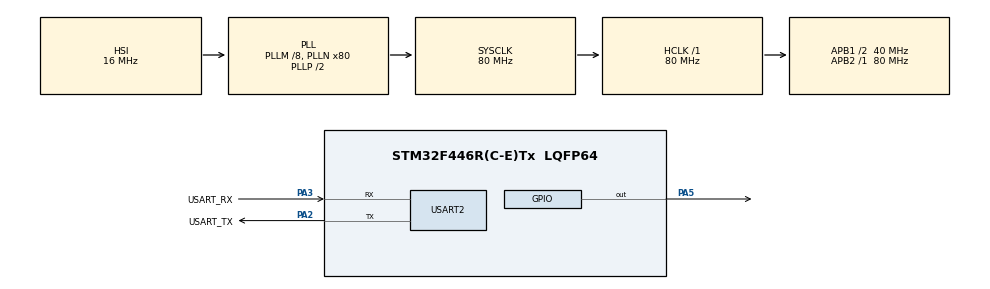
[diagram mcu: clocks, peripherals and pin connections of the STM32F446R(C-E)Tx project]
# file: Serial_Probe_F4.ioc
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Dma.Request0=USART2_RX
Dma.Request1=USART2_TX
Dma.USART2_RX.0.Direction=DMA_PERIPH_TO_MEMORY
Dma.USART2_RX.0.FIFOMode=DMA_FIFOMODE_DISABLE
Dma.USART2_RX.0.Instance=DMA1_Stream5
Dma.USART2_RX.0.MemDataAlignment=DMA_MDATAALIGN_BYTE
Dma.USART2_RX.0.MemInc=DMA_MINC_ENABLE
Dma.USART2_RX.0.Mode=DMA_CIRCULAR
Dma.USART2_RX.0.PeriphDataAlignment=DMA_PDATAALIGN_BYTE
Dma.USART2_RX.0.PeriphInc=DMA_PINC_DISABLE
Dma.USART2_RX.0.Priority=DMA_PRIORITY_LOW
Dma.USART2_TX.1.Direction=DMA_MEMORY_TO_PERIPH
Dma.USART2_TX.1.FIFOMode=DMA_FIFOMODE_DISABLE
Dma.USART2_TX.1.Instance=DMA1_Stream6
Dma.USART2_TX.1.MemDataAlignment=DMA_MDATAALIGN_BYTE
Dma.USART2_TX.1.MemInc=DMA_MINC_ENABLE
Dma.USART2_TX.1.Mode=DMA_NORMAL
Dma.USART2_TX.1.PeriphDataAlignment=DMA_PDATAALIGN_BYTE
Dma.USART2_TX.1.PeriphInc=DMA_PINC_DISABLE
Dma.USART2_TX.1.Priority=DMA_PRIORITY_LOW
Mcu.Family=STM32F4
Mcu.Name=STM32F446R(C-E)Tx
Mcu.Package=LQFP64
NVIC.DMA1_Stream5_IRQn=true\:1\:0\:true\:true\:true\:3\:false\:true\:true
NVIC.DMA1_Stream6_IRQn=true\:1\:0\:true\:true\:true\:2\:false\:true\:true
NVIC.PriorityGroup=NVIC_PRIORITYGROUP_4
NVIC.TIM6_DAC_IRQn=true\:1\:0\:true\:true\:true\:4\:true\:true\:true
NVIC.USART2_IRQn=true\:1\:0\:true\:true\:true\:1\:true\:true\:true
PA2.GPIO_Label=USART_TX
PA2.Mode=Asynchronous
PA2.Signal=USART2_TX
PA3.GPIO_Label=USART_RX
PA3.Mode=Asynchronous
PA3.Signal=USART2_RX
PA5.Signal=GPIO_Output
ProjectManager.HeapSize=0x200
ProjectManager.StackSize=0x400
ProjectManager.TargetToolchain=STM32CubeIDE
RCC.48MHZClocksFreq_Value=84000000
RCC.AHBFreq_Value=80000000
RCC.APB1CLKDivider=RCC_HCLK_DIV2
RCC.APB1Freq_Value=40000000
RCC.APB1TimFreq_Value=80000000
RCC.APB2Freq_Value=80000000
RCC.APB2TimFreq_Value=80000000
RCC.CortexFreq_Value=80000000
RCC.FLatency-AdvancedSettings=FLASH_LATENCY_2
RCC.HCLKFreq_Value=80000000
RCC.HSE_VALUE=8000000
RCC.HSI_VALUE=16000000
RCC.PLLM=8
RCC.PLLN=80
RCC.SYSCLKFreq_VALUE=80000000
RCC.SYSCLKSource=RCC_SYSCLKSOURCE_PLLCLK
RCC.USBFreq_Value=80000000
RCC.VCOOutputFreq_Value=160000000
TIM6.Period=99
TIM6.Prescaler=7999
USART2.VirtualMode=VM_ASYNC
VP_TIM6_VS_ClockSourceINT.Mode=Enable_Timer
board=NUCLEO-F446RE

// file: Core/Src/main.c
/* USER CODE BEGIN Header */
/**
  ******************************************************************************
  * @file           : main.c
  * @brief          : Main program body
  ******************************************************************************
  * @attention
  *
  * Copyright (c) 2025 STMicroelectronics.
  * All rights reserved.
  *
  * This software is licensed under terms that can be found in the LICENSE file
  * in the root directory of this software component.
  * If no LICENSE file comes with this software, it is provided AS-IS.
  *
  ******************************************************************************
  */
/* USER CODE END Header */
#include "main.h"
#include "dma.h"
#include "tim.h"
#include "usart.h"
#include "gpio.h"

/* USER CODE BEGIN PD */
#define MODE 2 // 0 IT, 1 DMA, 2 BUSY
/* USER CODE END PD */

/* USER CODE BEGIN PV */
uint8_t TX_TIM6_f = 0;
uint8_t TX_UART_f = 0;
uint8_t uart_buff = 0;
uint8_t TX_Packet[8] = {0xbb, 0x00, 0x01, 0x00, 0x01, 0x00, 0x01, 0xee};
/* USER CODE END PV */

void SystemClock_Config(void);
static void MX_NVIC_Init(void);

int main(void)
{

  /* MCU Configuration--------------------------------------------------------*/

  /* Reset of all peripherals, Initializes the Flash interface and the Systick. */
  HAL_Init();

  /* Configure the system clock */
  SystemClock_Config();

  /* Initialize all configured peripherals */
  MX_GPIO_Init();
  MX_DMA_Init();
  MX_USART2_UART_Init();
  MX_TIM6_Init();

  /* Initialize interrupts */
  MX_NVIC_Init();
  /* USER CODE BEGIN 2 */
  #if (MODE == 1)
  	  HAL_UART_Receive_DMA(&huart2, &uart_buff, 1);
  #elif (MODE == 0)
	  HAL_UART_Receive_IT(&huart2, &uart_buff, 1);
  #endif

  HAL_TIM_Base_Start_IT(&htim6);

  #if (MODE != 2)
  	  HAL_SuspendTick();
  	  HAL_PWR_EnableSleepOnExit();
  	  HAL_PWR_EnterSLEEPMode(PWR_MAINREGULATOR_ON, PWR_SLEEPENTRY_WFI);
  #endif
  /* USER CODE END 2 */

  /* Infinite loop */
  while (1)
  {

    /* USER CODE BEGIN 3 */
	#if (MODE == 2)
	  if (HAL_UART_Receive(&huart2, &uart_buff, 1, 10) == HAL_OK) {
		  HAL_UART_Transmit(&huart2, &uart_buff, 1, 10);
	  }
	  if (TX_TIM6_f) {
		  TX_TIM6_f = 0;
		  HAL_UART_Transmit(&huart2, TX_Packet, 8, 10);
	  }
	#endif
  }
  /* USER CODE END 3 */
}

void SystemClock_Config(void)
{
  RCC_OscInitTypeDef RCC_OscInitStruct = {0};
  RCC_ClkInitTypeDef RCC_ClkInitStruct = {0};

  /** Configure the main internal regulator output voltage
  */
  __HAL_RCC_PWR_CLK_ENABLE();
  __HAL_PWR_VOLTAGESCALING_CONFIG(PWR_REGULATOR_VOLTAGE_SCALE3);

  /** Initializes the RCC Oscillators according to the specified parameters
  * in the RCC_OscInitTypeDef structure.
  */
  RCC_OscInitStruct.OscillatorType = RCC_OSCILLATORTYPE_HSI;
  RCC_OscInitStruct.HSIState = RCC_HSI_ON;
  RCC_OscInitStruct.HSICalibrationValue = RCC_HSICALIBRATION_DEFAULT;
  RCC_OscInitStruct.PLL.PLLState = RCC_PLL_ON;
  RCC_OscInitStruct.PLL.PLLSource = RCC_PLLSOURCE_HSI;
  RCC_OscInitStruct.PLL.PLLM = 8;
  RCC_OscInitStruct.PLL.PLLN = 80;
  RCC_OscInitStruct.PLL.PLLP = RCC_PLLP_DIV2;
  RCC_OscInitStruct.PLL.PLLQ = 2;
  RCC_OscInitStruct.PLL.PLLR = 2;
  if (HAL_RCC_OscConfig(&RCC_OscInitStruct) != HAL_OK)
  {
    Error_Handler();
  }

  /** Initializes the CPU, AHB and APB buses clocks
  */
  RCC_ClkInitStruct.ClockType = RCC_CLOCKTYPE_HCLK|RCC_CLOCKTYPE_SYSCLK
                              |RCC_CLOCKTYPE_PCLK1|RCC_CLOCKTYPE_PCLK2;
  RCC_ClkInitStruct.SYSCLKSource = RCC_SYSCLKSOURCE_PLLCLK;
  RCC_ClkInitStruct.AHBCLKDivider = RCC_SYSCLK_DIV1;
  RCC_ClkInitStruct.APB1CLKDivider = RCC_HCLK_DIV2;
  RCC_ClkInitStruct.APB2CLKDivider = RCC_HCLK_DIV1;

  if (HAL_RCC_ClockConfig(&RCC_ClkInitStruct, FLASH_LATENCY_2) != HAL_OK)
  {
    Error_Handler();
  }
}

/**
  * @brief NVIC Configuration.
  * @retval None
  */
static void MX_NVIC_Init(void)
{
  /* USART2_IRQn interrupt configuration */
  HAL_NVIC_SetPriority(USART2_IRQn, 1, 0);
  HAL_NVIC_EnableIRQ(USART2_IRQn);
  /* DMA1_Stream6_IRQn interrupt configuration */
  HAL_NVIC_SetPriority(DMA1_Stream6_IRQn, 1, 0);
  HAL_NVIC_EnableIRQ(DMA1_Stream6_IRQn);
  /* DMA1_Stream5_IRQn interrupt configuration */
  HAL_NVIC_SetPriority(DMA1_Stream5_IRQn, 1, 0);
  HAL_NVIC_EnableIRQ(DMA1_Stream5_IRQn);
  /* TIM6_DAC_IRQn interrupt configuration */
  HAL_NVIC_SetPriority(TIM6_DAC_IRQn, 1, 0);
  HAL_NVIC_EnableIRQ(TIM6_DAC_IRQn);
}

/* USER CODE BEGIN 4 */
void HAL_UART_RxCpltCallback(UART_HandleTypeDef *huart) {
	// LED On
	HAL_GPIO_WritePin(GPIOA, GPIO_PIN_5, 1);
	#if (MODE == 1)
		if (huart2.gState != HAL_UART_STATE_READY) {
			TX_UART_f = 1;
		} else HAL_UART_Transmit_DMA(&huart2, &uart_buff, 1);
	#elif (MODE == 0)
		if (huart2.gState != HAL_UART_STATE_READY) {
			TX_UART_f = 1;
		} else {
			HAL_UART_Transmit_IT(&huart2, &uart_buff, 1);
			HAL_UART_Receive_IT(&huart2, &uart_buff, 1);
		}
	#endif
}

void HAL_UART_TxCpltCallback(UART_HandleTypeDef *huart) {
	if (TX_UART_f) {
		TX_UART_f = 0;
		#if (MODE == 1)
			HAL_UART_Transmit_DMA(&huart2, &uart_buff, 1);
		#elif (MODE == 0)
			HAL_UART_Transmit_IT(&huart2, &uart_buff, 1);
			HAL_UART_Receive_IT(&huart2, &uart_buff, 1);
		#endif
	} else if (TX_TIM6_f) {
		TX_TIM6_f = 0;
		#if (MODE == 1)
			HAL_UART_Transmit_DMA(&huart2, TX_Packet, 8);
		#elif (MODE == 0)
			HAL_UART_Transmit_IT(&huart2, TX_Packet, 8);
		#endif
	}
	// LED Off
	HAL_GPIO_WritePin(GPIOA, GPIO_PIN_5, 0);
}

void HAL_TIM_PeriodElapsedCallback (TIM_HandleTypeDef *htim) {
	if (htim->Instance == TIM6) {
		#if (MODE == 1)
			if (huart2.gState != HAL_UART_STATE_READY) {
				TX_TIM6_f = 1;
			} else HAL_UART_Transmit_DMA(&huart2, TX_Packet, 8);
		#elif (MODE == 0)
			if (huart2.gState != HAL_UART_STATE_READY) {
				TX_TIM6_f = 1;
			} else HAL_UART_Transmit_IT(&huart2, TX_Packet, 8);
		#elif (MODE == 2)
			if (huart2.gState != HAL_UART_STATE_READY) {
				TX_TIM6_f = 1;
			} else HAL_UART_Transmit(&huart2, TX_Packet, 8, 10);
		#endif
	}
}
/* USER CODE END 4 */

void Error_Handler(void)
{
  __disable_irq();
  while (1)
  {
  }
}
